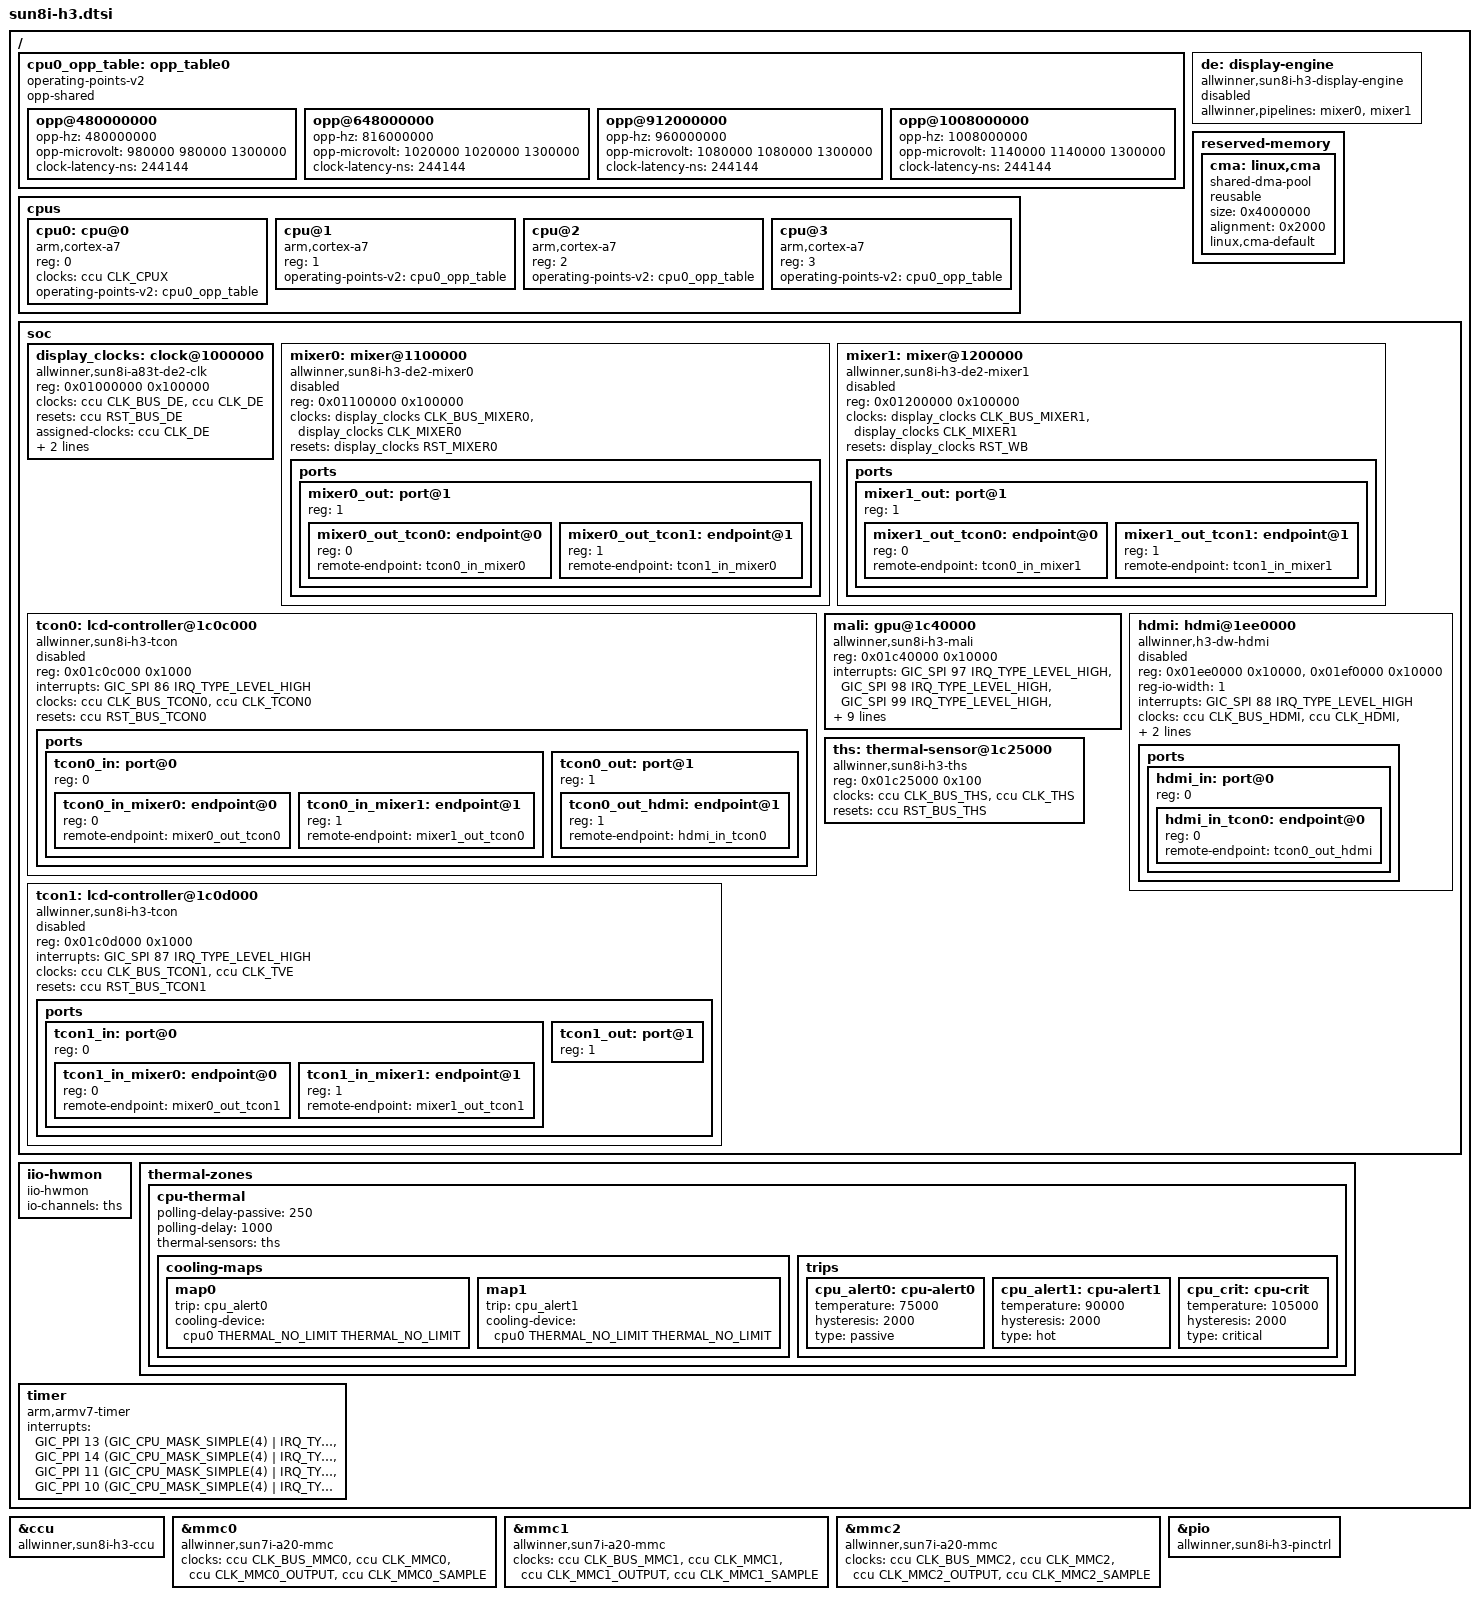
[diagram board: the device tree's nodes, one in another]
/*
 * Copyright (C) 2015 Jens Kuske <jenskuske@gmail.com>
 *
 * This file is dual-licensed: you can use it either under the terms
 * of the GPL or the X11 license, at your option. Note that this dual
 * licensing only applies to this file, and not this project as a
 * whole.
 *
 *  a) This file is free software; you can redistribute it and/or
 *     modify it under the terms of the GNU General Public License as
 *     published by the Free Software Foundation; either version 2 of the
 *     License, or (at your option) any later version.
 *
 *     This file is distributed in the hope that it will be useful,
 *     but WITHOUT ANY WARRANTY; without even the implied warranty of
 *     MERCHANTABILITY or FITNESS FOR A PARTICULAR PURPOSE.  See the
 *     GNU General Public License for more details.
 *
 * Or, alternatively,
 *
 *  b) Permission is hereby granted, free of charge, to any person
 *     obtaining a copy of this software and associated documentation
 *     files (the "Software"), to deal in the Software without
 *     restriction, including without limitation the rights to use,
 *     copy, modify, merge, publish, distribute, sublicense, and/or
 *     sell copies of the Software, and to permit persons to whom the
 *     Software is furnished to do so, subject to the following
 *     conditions:
 *
 *     The above copyright notice and this permission notice shall be
 *     included in all copies or substantial portions of the Software.
 *
 *     THE SOFTWARE IS PROVIDED "AS IS", WITHOUT WARRANTY OF ANY KIND,
 *     EXPRESS OR IMPLIED, INCLUDING BUT NOT LIMITED TO THE WARRANTIES
 *     OF MERCHANTABILITY, FITNESS FOR A PARTICULAR PURPOSE AND
 *     NONINFRINGEMENT. IN NO EVENT SHALL THE AUTHORS OR COPYRIGHT
 *     HOLDERS BE LIABLE FOR ANY CLAIM, DAMAGES OR OTHER LIABILITY,
 *     WHETHER IN AN ACTION OF CONTRACT, TORT OR OTHERWISE, ARISING
 *     FROM, OUT OF OR IN CONNECTION WITH THE SOFTWARE OR THE USE OR
 *     OTHER DEALINGS IN THE SOFTWARE.
 */

#include "sunxi-h3-h5.dtsi"
#include <dt-bindings/clock/sun8i-de2.h>
#include <dt-bindings/reset/sun8i-de2.h>
#include <dt-bindings/thermal/thermal.h>

/ {
	cpu0_opp_table: opp_table0 {
		compatible = "operating-points-v2";
		opp-shared;

		opp@480000000 {
			opp-hz = /bits/ 64 <480000000>;
			opp-microvolt = <980000 980000 1300000>;
			clock-latency-ns = <244144>; /* 8 32k periods */
		};

		opp@648000000 {
			opp-hz = /bits/ 64 <816000000>;
			opp-microvolt = <1020000 1020000 1300000>;
			clock-latency-ns = <244144>; /* 8 32k periods */
		};

		opp@912000000 {
			opp-hz = /bits/ 64 <960000000>;
			opp-microvolt = <1080000 1080000 1300000>;
			clock-latency-ns = <244144>; /* 8 32k periods */
		};

		opp@1008000000 {
			opp-hz = /bits/ 64 <1008000000>;
			opp-microvolt = <1140000 1140000 1300000>;
			clock-latency-ns = <244144>; /* 8 32k periods */
		};
	};

	cpus {
		#address-cells = <1>;
		#size-cells = <0>;

		cpu0: cpu@0 {
			compatible = "arm,cortex-a7";
			device_type = "cpu";
			reg = <0>;
			clocks = <&ccu CLK_CPUX>;
			clock-names = "cpu";
			operating-points-v2 = <&cpu0_opp_table>;
			#cooling-cells = <0x2>;
		};

		cpu@1 {
			compatible = "arm,cortex-a7";
			device_type = "cpu";
			reg = <1>;
			operating-points-v2 = <&cpu0_opp_table>;
		};

		cpu@2 {
			compatible = "arm,cortex-a7";
			device_type = "cpu";
			reg = <2>;
			operating-points-v2 = <&cpu0_opp_table>;
		};

		cpu@3 {
			compatible = "arm,cortex-a7";
			device_type = "cpu";
			reg = <3>;
			operating-points-v2 = <&cpu0_opp_table>;
		};
	};

	de: display-engine {
		compatible = "allwinner,sun8i-h3-display-engine";
		allwinner,pipelines = <&mixer0>,
				      <&mixer1>;
		status = "disabled";
	};

	reserved-memory {
		#address-cells = <1>;
		#size-cells = <1>;
		ranges;

		cma: linux,cma {
			compatible = "shared-dma-pool";
			reusable;
			size = <0x4000000>;
			alignment = <0x2000>;
			linux,cma-default;
		};
	};

	soc {
		display_clocks: clock@1000000 {
			compatible = "allwinner,sun8i-a83t-de2-clk";
			reg = <0x01000000 0x100000>;
			clocks = <&ccu CLK_BUS_DE>,
				 <&ccu CLK_DE>;
			clock-names = "bus",
				      "mod";
			resets = <&ccu RST_BUS_DE>;
			#clock-cells = <1>;
			#reset-cells = <1>;
			assigned-clocks = <&ccu CLK_DE>;
			assigned-clock-parents = <&ccu CLK_PLL_DE>;
			assigned-clock-rates = <432000000>;
		};

		mixer0: mixer@1100000 {
			compatible = "allwinner,sun8i-h3-de2-mixer0";
			reg = <0x01100000 0x100000>;
			clocks = <&display_clocks CLK_BUS_MIXER0>,
				 <&display_clocks CLK_MIXER0>;
			clock-names = "bus",
				      "mod";
			resets = <&display_clocks RST_MIXER0>;
			status = "disabled";

			ports {
				#address-cells = <1>;
				#size-cells = <0>;

				mixer0_out: port@1 {
					#address-cells = <1>;
					#size-cells = <0>;
					reg = <1>;

					mixer0_out_tcon0: endpoint@0 {
						reg = <0>;
						remote-endpoint = <&tcon0_in_mixer0>;
					};

					mixer0_out_tcon1: endpoint@1 {
						reg = <1>;
						remote-endpoint = <&tcon1_in_mixer0>;
					};
				};
			};
		};

		mixer1: mixer@1200000 {
			compatible = "allwinner,sun8i-h3-de2-mixer1";
			reg = <0x01200000 0x100000>;
			clocks = <&display_clocks CLK_BUS_MIXER1>,
				 <&display_clocks CLK_MIXER1>;
			clock-names = "bus",
				      "mod";
			resets = <&display_clocks RST_WB>;
			status = "disabled";

			ports {
				#address-cells = <1>;
				#size-cells = <0>;

				mixer1_out: port@1 {
					#address-cells = <1>;
					#size-cells = <0>;
					reg = <1>;

					mixer1_out_tcon0: endpoint@0 {
						reg = <0>;
						remote-endpoint = <&tcon0_in_mixer1>;
					};

					mixer1_out_tcon1: endpoint@1 {
						reg = <1>;
						remote-endpoint = <&tcon1_in_mixer1>;
					};
				};
			};
		};

		tcon0: lcd-controller@1c0c000 {
			compatible = "allwinner,sun8i-h3-tcon";
			reg = <0x01c0c000 0x1000>;
			interrupts = <GIC_SPI 86 IRQ_TYPE_LEVEL_HIGH>;
			clocks = <&ccu CLK_BUS_TCON0>,
				 <&ccu CLK_TCON0>;
			clock-names = "ahb",
				      "tcon-ch1";
			resets = <&ccu RST_BUS_TCON0>;
			reset-names = "lcd";
			status = "disabled";

			ports {
				#address-cells = <1>;
				#size-cells = <0>;

				tcon0_in: port@0 {
					#address-cells = <1>;
					#size-cells = <0>;
					reg = <0>;

					tcon0_in_mixer0: endpoint@0 {
						reg = <0>;
						remote-endpoint = <&mixer0_out_tcon0>;
					};

					tcon0_in_mixer1: endpoint@1 {
						reg = <1>;
						remote-endpoint = <&mixer1_out_tcon0>;
					};
				};

				tcon0_out: port@1 {
					#address-cells = <1>;
					#size-cells = <0>;
					reg = <1>;

					tcon0_out_hdmi: endpoint@1 {
						reg = <1>;
						remote-endpoint = <&hdmi_in_tcon0>;
					};
				};
			};
		};

		tcon1: lcd-controller@1c0d000 {
			compatible = "allwinner,sun8i-h3-tcon";
			reg = <0x01c0d000 0x1000>;
			interrupts = <GIC_SPI 87 IRQ_TYPE_LEVEL_HIGH>;
			clocks = <&ccu CLK_BUS_TCON1>,
				 <&ccu CLK_TVE>;
			clock-names = "ahb",
				      "tcon-ch1";
			resets = <&ccu RST_BUS_TCON1>;
			reset-names = "lcd";
			status = "disabled";

			ports {
				#address-cells = <1>;
				#size-cells = <0>;

				tcon1_in: port@0 {
					#address-cells = <1>;
					#size-cells = <0>;
					reg = <0>;

					tcon1_in_mixer0: endpoint@0 {
						reg = <0>;
						remote-endpoint = <&mixer0_out_tcon1>;
					};

					tcon1_in_mixer1: endpoint@1 {
						reg = <1>;
						remote-endpoint = <&mixer1_out_tcon1>;
					};
				};

				tcon1_out: port@1 {
					#address-cells = <1>;
					#size-cells = <0>;
					reg = <1>;
				};
			};
		};

		mali: gpu@1c40000 {
			compatible = "allwinner,sun8i-h3-mali",
				     "allwinner,sun7i-a20-mali", "arm,mali-400";
			reg = <0x01c40000 0x10000>;
			interrupts = <GIC_SPI 97 IRQ_TYPE_LEVEL_HIGH>,
				     <GIC_SPI 98 IRQ_TYPE_LEVEL_HIGH>,
				     <GIC_SPI 99 IRQ_TYPE_LEVEL_HIGH>,
				     <GIC_SPI 100 IRQ_TYPE_LEVEL_HIGH>,
				     <GIC_SPI 102 IRQ_TYPE_LEVEL_HIGH>,
				     <GIC_SPI 103 IRQ_TYPE_LEVEL_HIGH>,
				     <GIC_SPI 101 IRQ_TYPE_LEVEL_HIGH>;
			interrupt-names = "gp",
					  "gpmmu",
					  "pp0",
					  "ppmmu0",
					  "pp1",
					  "ppmmu1",
					  "pmu";
			clocks = <&ccu CLK_BUS_GPU>, <&ccu CLK_GPU>;
			clock-names = "bus", "core";
			resets = <&ccu RST_BUS_GPU>;
			memory-region = <&cma>;

			assigned-clocks = <&ccu CLK_GPU>;
			assigned-clock-rates = <384000000>;
		};

		hdmi: hdmi@1ee0000 {
			compatible = "allwinner,h3-dw-hdmi";
			reg = <0x01ee0000 0x10000>,
			      <0x01ef0000 0x10000>;
			reg-io-width = <1>;
			interrupts = <GIC_SPI 88 IRQ_TYPE_LEVEL_HIGH>;
			clocks = <&ccu CLK_BUS_HDMI>, <&ccu CLK_HDMI>,
				 <&ccu CLK_HDMI_DDC>;
			clock-names = "iahb", "isfr", "iddc";
			resets = <&ccu RST_BUS_HDMI0>, <&ccu RST_BUS_HDMI1>;
			reset-names = "hdmi", "ddc";
			status = "disabled";

			ports {
				#address-cells = <1>;
				#size-cells = <0>;

				hdmi_in: port@0 {
					#address-cells = <1>;
					#size-cells = <0>;
					reg = <0>;

					hdmi_in_tcon0: endpoint@0 {
						reg = <0>;
						remote-endpoint = <&tcon0_out_hdmi>;
					};
				};
			};
		};
	};

	iio-hwmon {
		compatible = "iio-hwmon";
		io-channels = <&ths>;
	};

	soc {
		ths: thermal-sensor@1c25000 {
			compatible = "allwinner,sun8i-h3-ths";
			reg = <0x01c25000 0x100>;
			clocks = <&ccu CLK_BUS_THS>, <&ccu CLK_THS>;
			clock-names = "bus", "mod";
			resets = <&ccu RST_BUS_THS>;
			#thermal-sensor-cells = <0>;
			#io-channel-cells = <0>;
		};
	};

	thermal-zones {
		cpu-thermal {
			/* milliseconds */
			polling-delay-passive = <250>;
			polling-delay = <1000>;
			thermal-sensors = <&ths>;

			cooling-maps {
				map0 {
					trip = <&cpu_alert0>;
					cooling-device = <&cpu0 THERMAL_NO_LIMIT THERMAL_NO_LIMIT>;
				};
				map1 {
					trip = <&cpu_alert1>;
					cooling-device = <&cpu0 THERMAL_NO_LIMIT THERMAL_NO_LIMIT>;
				};
			};

			trips {
				cpu_alert0: cpu-alert0 {
					/* milliCelsius */
					temperature = <75000>;
					hysteresis = <2000>;
					type = "passive";
				};

				cpu_alert1: cpu-alert1 {
					/* milliCelsius */
					temperature = <90000>;
					hysteresis = <2000>;
					type = "hot";
				};

				cpu_crit: cpu-crit {
					/* milliCelsius */
					temperature = <105000>;
					hysteresis = <2000>;
					type = "critical";
				};
			};
		};
	};

	timer {
		compatible = "arm,armv7-timer";
		interrupts = <GIC_PPI 13 (GIC_CPU_MASK_SIMPLE(4) | IRQ_TYPE_LEVEL_LOW)>,
			     <GIC_PPI 14 (GIC_CPU_MASK_SIMPLE(4) | IRQ_TYPE_LEVEL_LOW)>,
			     <GIC_PPI 11 (GIC_CPU_MASK_SIMPLE(4) | IRQ_TYPE_LEVEL_LOW)>,
			     <GIC_PPI 10 (GIC_CPU_MASK_SIMPLE(4) | IRQ_TYPE_LEVEL_LOW)>;
	};
};

&ccu {
	compatible = "allwinner,sun8i-h3-ccu";
};

&mmc0 {
	compatible = "allwinner,sun7i-a20-mmc";
	clocks = <&ccu CLK_BUS_MMC0>,
		 <&ccu CLK_MMC0>,
		 <&ccu CLK_MMC0_OUTPUT>,
		 <&ccu CLK_MMC0_SAMPLE>;
	clock-names = "ahb",
		      "mmc",
		      "output",
		      "sample";
};

&mmc1 {
	compatible = "allwinner,sun7i-a20-mmc";
	clocks = <&ccu CLK_BUS_MMC1>,
		 <&ccu CLK_MMC1>,
		 <&ccu CLK_MMC1_OUTPUT>,
		 <&ccu CLK_MMC1_SAMPLE>;
	clock-names = "ahb",
		      "mmc",
		      "output",
		      "sample";
};

&mmc2 {
	compatible = "allwinner,sun7i-a20-mmc";
	clocks = <&ccu CLK_BUS_MMC2>,
		 <&ccu CLK_MMC2>,
		 <&ccu CLK_MMC2_OUTPUT>,
		 <&ccu CLK_MMC2_SAMPLE>;
	clock-names = "ahb",
		      "mmc",
		      "output",
		      "sample";
};

&pio {
	compatible = "allwinner,sun8i-h3-pinctrl";
};
